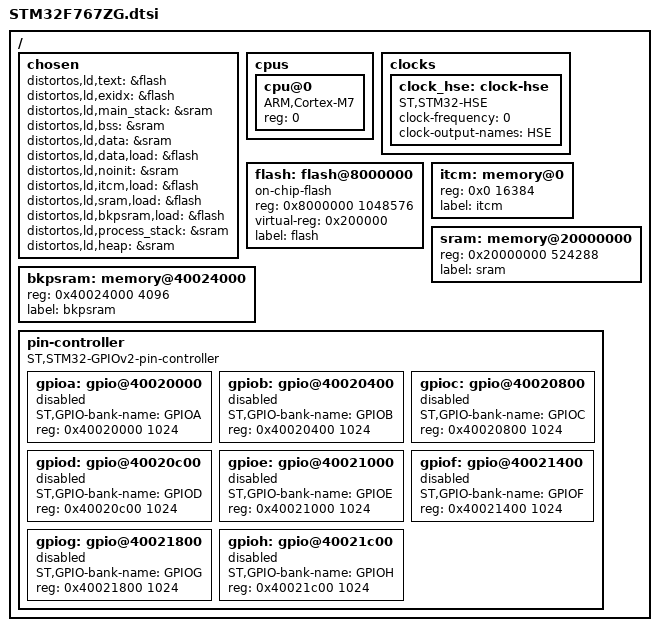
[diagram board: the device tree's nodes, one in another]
/**
 * \file
 * \brief Devicetree fragment for STM32F767ZG
 *
 * \author Copyright (C) 2014-2017 Kamil Szczygiel http://www.distortec.com http://www.freddiechopin.info
 *
 * \par License
 * This Source Code Form is subject to the terms of the Mozilla Public License, v. 2.0. If a copy of the MPL was not
 * distributed with this file, You can obtain one at http://mozilla.org/MPL/2.0/.
 *
 * \warning
 * Automatically generated file - do not edit!
 */

#include "ARMv7-M.dtsi"

/ {
	chosen {
		distortos,ld,text = &flash;
		distortos,ld,exidx = &flash;
		distortos,ld,main_stack = &sram;
		distortos,ld,bss = &sram;
		distortos,ld,data = &sram;
		distortos,ld,data,load = &flash;
		distortos,ld,noinit = &sram;
		distortos,ld,itcm,load = &flash;
		distortos,ld,sram,load = &flash;
		distortos,ld,bkpsram,load = &flash;
		distortos,ld,process_stack = &sram;
		distortos,ld,heap = &sram;
	};

	cpus {
		#address-cells = <1>;
		#size-cells = <0>;

		cpu@0 {
			compatible = "ARM,Cortex-M7", "ARM,ARMv7-M";
			device_type = "cpu";
			reg = <0>;
		};
	};

	clocks {
		clock_hse: clock-hse {
			#clock-cells = <0>;
			compatible = "ST,STM32-HSE", "fixed-clock";
			clock-frequency = <0>;
			clock-output-names = "HSE";
		};
	};

	flash: flash@8000000 {
		compatible = "on-chip-flash";
		reg = <0x8000000 1048576>;
		virtual-reg = <0x200000>;
		label = "flash";
	};

	itcm: memory@0 {
		device_type = "memory";
		reg = <0x0 16384>;
		label = "itcm";
	};

	sram: memory@20000000 {
		device_type = "memory";
		reg = <0x20000000 524288>;
		label = "sram";
	};

	bkpsram: memory@40024000 {
		device_type = "memory";
		reg = <0x40024000 4096>;
		label = "bkpsram";
	};

	pin-controller {
		compatible = "ST,STM32-GPIOv2-pin-controller";
		ranges;
	};

	pin-controller {
		gpioa: gpio@40020000 {
			ST,GPIO-bank-name = "GPIOA";
			#gpio-cells = <2>;
			reg = <0x40020000 1024>;
			status = "disabled";
		};
	};

	pin-controller {
		gpiob: gpio@40020400 {
			ST,GPIO-bank-name = "GPIOB";
			#gpio-cells = <2>;
			reg = <0x40020400 1024>;
			status = "disabled";
		};
	};

	pin-controller {
		gpioc: gpio@40020800 {
			ST,GPIO-bank-name = "GPIOC";
			#gpio-cells = <2>;
			reg = <0x40020800 1024>;
			status = "disabled";
		};
	};

	pin-controller {
		gpiod: gpio@40020c00 {
			ST,GPIO-bank-name = "GPIOD";
			#gpio-cells = <2>;
			reg = <0x40020c00 1024>;
			status = "disabled";
		};
	};

	pin-controller {
		gpioe: gpio@40021000 {
			ST,GPIO-bank-name = "GPIOE";
			#gpio-cells = <2>;
			reg = <0x40021000 1024>;
			status = "disabled";
		};
	};

	pin-controller {
		gpiof: gpio@40021400 {
			ST,GPIO-bank-name = "GPIOF";
			#gpio-cells = <2>;
			reg = <0x40021400 1024>;
			status = "disabled";
		};
	};

	pin-controller {
		gpiog: gpio@40021800 {
			ST,GPIO-bank-name = "GPIOG";
			#gpio-cells = <2>;
			reg = <0x40021800 1024>;
			status = "disabled";
		};
	};

	pin-controller {
		gpioh: gpio@40021c00 {
			ST,GPIO-bank-name = "GPIOH";
			#gpio-cells = <2>;
			reg = <0x40021c00 1024>;
			status = "disabled";
		};
	};
};
